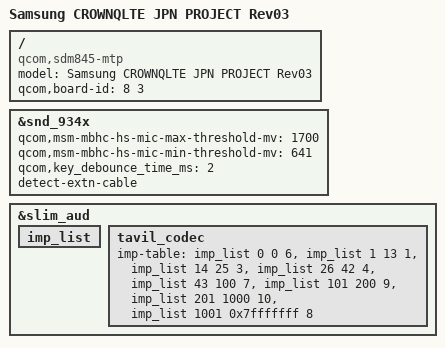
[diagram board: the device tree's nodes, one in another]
/* Copyright (c) 2016-2017, The Linux Foundation. All rights reserved.
 *
 * This program is free software; you can redistribute it and/or modify
 * it under the terms of the GNU General Public License version 2 and
 * only version 2 as published by the Free Software Foundation.
 *
 * This program is distributed in the hope that it will be useful,
 * but WITHOUT ANY WARRANTY; without even the implied warranty of
 * MERCHANTABILITY or FITNESS FOR A PARTICULAR PURPOSE.  See the
 * GNU General Public License for more details.
 */

/dts-v1/;

#include "../qcom/sdm845-v2.1.dtsi"
#include "../qcom/sdm845-mtp.dtsi"
#include "sdm845-sec-common.dtsi"
#include "sdm845-sec-crownqlte-pm-common.dtsi"
#include "sdm845-sec-crownqlte-pm-r02.dtsi"
#include "sdm845-sec-crownqlte-pm-jpn-r03.dtsi"
#include "sdm845-sec-crownqlte-r03.dtsi"
#include "sdm845-sec-crownqlte-pinctrl-r03.dtsi"
#include "battery-data-crownq-common.dtsi"
#include "sdm845-sec-crownqlte-display-r00.dtsi"
#include "sdm845-sec-crownqlte-displayport-r00.dtsi"
#include "sdm845-sec-crownqlte-fingerprint-sensor-r04.dtsi"
#include "sdm845-sec-starqlte-mst-r00.dtsi"
#include "sdm845-camera-sensor-crownqlte-r00.dtsi"
#include "sdm845-starq-max77705.dtsi"
#include "sdm845-sec-crownqlte-jpn-felica-r03.dtsi"
#include "sdm845-sec-crownqlte-jpn-isdbt-r03.dtsi"

/ {
	model = "Samsung CROWNQLTE JPN PROJECT Rev03";
	compatible = "qcom,sdm845-mtp", "qcom,sdm845", "qcom,mtp";
	qcom,board-id = <8 3>;
};

&snd_934x {
	qcom,msm-mbhc-hs-mic-max-threshold-mv = <1700>;
	qcom,msm-mbhc-hs-mic-min-threshold-mv = <641>;
	qcom,key_debounce_time_ms = <2>;
	detect-extn-cable;
};

&slim_aud {
	imp_list: imp_list {
		#list-imp-cells = <3>;
	};

	tavil_codec {
		imp-table = <&imp_list 0 0 6>,
				 <&imp_list 1 13 1>,
				 <&imp_list 14 25 3>,
				 <&imp_list 26 42 4>,
				 <&imp_list 43 100 7>,
				 <&imp_list 101 200 9>,
				 <&imp_list 201 1000 10>,
				 <&imp_list 1001 0x7fffffff 8>;
	};
};

